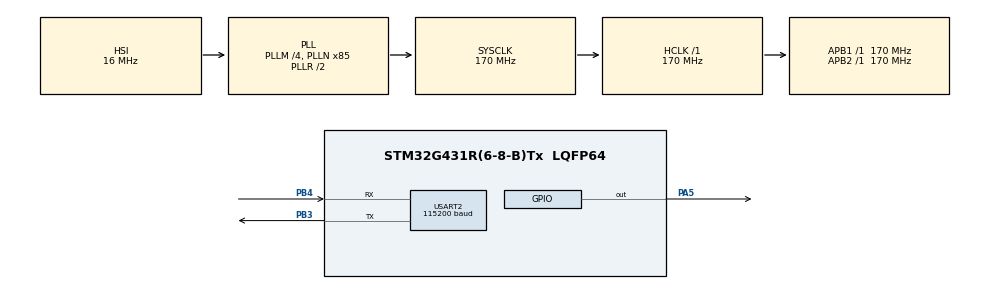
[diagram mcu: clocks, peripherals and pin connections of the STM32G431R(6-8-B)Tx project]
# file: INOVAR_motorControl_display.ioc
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Mcu.Family=STM32G4
Mcu.Name=STM32G431R(6-8-B)Tx
Mcu.Package=LQFP64
NVIC.PriorityGroup=NVIC_PRIORITYGROUP_4
NVIC.TIM1_UP_TIM16_IRQn=true\:15\:0\:false\:false\:true\:false\:true
NVIC.TimeBase=TIM1_UP_TIM16_IRQn
NVIC.TimeBaseIP=TIM1
NVIC.USART2_IRQn=true\:0\:0\:false\:false\:true\:true\:true
PA5.Signal=GPIO_Output
PB3.Mode=Asynchronous
PB3.Signal=USART2_TX
PB4.Mode=Asynchronous
PB4.Signal=USART2_RX
PF0-OSC_IN.Mode=HSE-External-Oscillator
PF0-OSC_IN.Signal=RCC_OSC_IN
PF1-OSC_OUT.Mode=HSE-External-Oscillator
PF1-OSC_OUT.Signal=RCC_OSC_OUT
ProjectManager.HeapSize=0x200
ProjectManager.StackSize=0x400
ProjectManager.TargetToolchain=STM32CubeIDE
RCC.ADC12Freq_Value=170000000
RCC.AHBFreq_Value=170000000
RCC.APB1Freq_Value=170000000
RCC.APB1TimFreq_Value=170000000
RCC.APB2Freq_Value=170000000
RCC.APB2TimFreq_Value=170000000
RCC.CortexFreq_Value=170000000
RCC.EXTERNAL_CLOCK_VALUE=12288000
RCC.HCLKFreq_Value=170000000
RCC.HSE_VALUE=24000000
RCC.HSI48_VALUE=48000000
RCC.HSI_VALUE=16000000
RCC.LSE_VALUE=32768
RCC.PLLM=RCC_PLLM_DIV4
RCC.PLLN=85
RCC.RTCClockSelection=RCC_RTCCLKSOURCE_LSE
RCC.SYSCLKFreq_VALUE=170000000
RCC.SYSCLKSource=RCC_SYSCLKSOURCE_PLLCLK
RCC.USBFreq_Value=170000000
RCC.VCOOutputFreq_Value=340000000
USART2.BaudRate=115200
USART2.VirtualMode-Asynchronous=VM_ASYNC
VP_SYS_VS_DBSignals.Mode=DisableDeadBatterySignals
VP_SYS_VS_tim1.Mode=TIM1
board=NUCLEO-G431RB

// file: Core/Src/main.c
/* USER CODE BEGIN Header */
/**
  ******************************************************************************
  * @file           : main.c
  * @brief          : Main program body
  ******************************************************************************
  * @attention
  *
  * <h2><center>&copy; Copyright (c) 2021 STMicroelectronics.
  * All rights reserved.</center></h2>
  *
  * This software component is licensed by ST under BSD 3-Clause license,
  * the "License"; You may not use this file except in compliance with the
  * License. You may obtain a copy of the License at:
  *                        opensource.org/licenses/BSD-3-Clause
  *
  ******************************************************************************
  */
/* USER CODE END Header */
#include "main.h"

UART_HandleTypeDef huart2;

/* USER CODE BEGIN PV */
uint16_t data,flash_data=0;
/* USER CODE END PV */

void SystemClock_Config(void);
static void MX_GPIO_Init(void);
static void MX_USART2_UART_Init(void);

/* USER CODE BEGIN 0 */

uint32_t rxBuff;
uint16_t buffCounter=0;
uint8_t buffDisplay[99];
 uint8_t Sifrem[4];
 uint8_t Sifrem1[4];
int q,w,e,r,g;
int z,x,c,v;
static uint8_t dataread[4];
uint8_t gelenData_24[4];
uint32_t sayi;
float sayi_;
int i,m,u;
char buff[100];
char buff1[100];

extern bool vitrinac;

extern bool vitrinsifre;

extern bool sifredegis;
//const char rxBuf[20];
//
//uint8_t gelen_mesaj_kutusu[8];
//extern int v,sifrem;
//
//
//uint8_t r;
//uint16_t i,n,m,z;

uint8_t Cmd_End[3] = {0xFF,0xFF,0xFF};

void NEXTION_SendString (char *ID, char *string)
{
	char buf[50];
	int len = sprintf (buf, "%s\%s", ID, string);
	HAL_UART_Transmit(&huart2, (uint8_t *)buf, len, 1000);
	HAL_UART_Transmit(&huart2, Cmd_End, 3, 100);
}

 void SendtoGauge (char *obj, float num, int dp)
 {
	 int32_t number = num*(pow(10,dp));

	 uint8_t *buffer = malloc(30*sizeof(char));

	 int len = sprintf((char *)buffer, "%s.val=%d", obj,number);
	 HAL_UART_Transmit(&huart2, buffer, len, 99);
	 HAL_UART_Transmit(&huart2, Cmd_End, 3, 100);

	 free(buffer);
 }
 void Nextion_Set_Text(char *object_name, char *buffer)
 {
 	char buf[120] = { 0 };
 	char sps = 0xFF;
 	sprintf(buf, "%s.txt=\"%s\"%c%c%c", object_name, buffer, sps, sps, sps);
 	HAL_UART_Transmit(&huart2, (uint8_t*) &buf, strlen(buf), 1000);
 }
/* USER CODE END 0 */

int main(void)
{

  /* MCU Configuration--------------------------------------------------------*/

  /* Reset of all peripherals, Initializes the Flash interface and the Systick. */
  HAL_Init();

  /* Configure the system clock */
  SystemClock_Config();

  /* Initialize all configured peripherals */
  MX_GPIO_Init();
  MX_USART2_UART_Init();
  ee_init();
  /* USER CODE BEGIN 2 */
  __HAL_UART_ENABLE_IT(&huart2, UART_IT_RXNE);

  //static uint8_t datawrite[4] = {1,2,3,4};
  static uint8_t dataread[4];
//  ee_write(0,4,datawrite);
//  ee_read(0,4,dataread);

  ee_read(0,4,dataread);

  /* USER CODE END 2 */

  /* Infinite loop */
  while (1)
  {

    /* USER CODE BEGIN 3 */

	  //Nextion_Set_Text("t1", "SIFRE GIRINIZ");
	     //sayi=(int*)Sifrem;

		// ee_write(0,4,Sifrem),

//	  if(strstr(rxBuf,"SETTING")!=NULL)
//	  {
//		  NEXTION_SendString("page ","5");
//		  memset(rxBuf,'0',sizeof(rxBuf));
//	  }
//	  if(strstr(rxBuf,"@PSWORD_PAGE")!=NULL)
//	  {
//		  NEXTION_SendString("page ","4");
//		  memset(rxBuf,'0',sizeof(rxBuf));
//	  }
//	  if(strstr(rxBuf,"@SIFREM")!=NULL)
//	  {
//		  NEXTION_SendString("page ","4");
//		  if(v==1782)
//		  {
//			  NEXTION_SendString("page ","1");
//		  }
//	  }
//	  if(strstr(rxBuf,"OPENTHEDOOR")!=NULL)
//	  {
//		  NEXTION_SendString("page ","4");
//		  if(v==1782)
//		  {
//			  NEXTION_SendString("page ","2");
//		  }
//	  }
//	  if(strstr(rxBuf,"START")!=NULL)
//	  {
//		  NEXTION_SendString("page ","3");
//		  memset(rxBuf,'0',sizeof(rxBuf));
//
//	  }
//	  if(strstr(rxBuf,"STOP")!=NULL)
//	  {
//		  NEXTION_SendString("page ","2");
//		  memset(rxBuf,'0',sizeof(rxBuf));
//
//	  }

  }
  /* USER CODE END 3 */
}

void SystemClock_Config(void)
{
  RCC_OscInitTypeDef RCC_OscInitStruct = {0};
  RCC_ClkInitTypeDef RCC_ClkInitStruct = {0};
  RCC_PeriphCLKInitTypeDef PeriphClkInit = {0};

  /** Configure the main internal regulator output voltage
  */
  HAL_PWREx_ControlVoltageScaling(PWR_REGULATOR_VOLTAGE_SCALE1_BOOST);
  /** Initializes the RCC Oscillators according to the specified parameters
  * in the RCC_OscInitTypeDef structure.
  */
  RCC_OscInitStruct.OscillatorType = RCC_OSCILLATORTYPE_HSI;
  RCC_OscInitStruct.HSIState = RCC_HSI_ON;
  RCC_OscInitStruct.HSICalibrationValue = RCC_HSICALIBRATION_DEFAULT;
  RCC_OscInitStruct.PLL.PLLState = RCC_PLL_ON;
  RCC_OscInitStruct.PLL.PLLSource = RCC_PLLSOURCE_HSI;
  RCC_OscInitStruct.PLL.PLLM = RCC_PLLM_DIV4;
  RCC_OscInitStruct.PLL.PLLN = 85;
  RCC_OscInitStruct.PLL.PLLP = RCC_PLLP_DIV2;
  RCC_OscInitStruct.PLL.PLLQ = RCC_PLLQ_DIV2;
  RCC_OscInitStruct.PLL.PLLR = RCC_PLLR_DIV2;
  if (HAL_RCC_OscConfig(&RCC_OscInitStruct) != HAL_OK)
  {
    Error_Handler();
  }
  /** Initializes the CPU, AHB and APB buses clocks
  */
  RCC_ClkInitStruct.ClockType = RCC_CLOCKTYPE_HCLK|RCC_CLOCKTYPE_SYSCLK
                              |RCC_CLOCKTYPE_PCLK1|RCC_CLOCKTYPE_PCLK2;
  RCC_ClkInitStruct.SYSCLKSource = RCC_SYSCLKSOURCE_PLLCLK;
  RCC_ClkInitStruct.AHBCLKDivider = RCC_SYSCLK_DIV1;
  RCC_ClkInitStruct.APB1CLKDivider = RCC_HCLK_DIV1;
  RCC_ClkInitStruct.APB2CLKDivider = RCC_HCLK_DIV1;

  if (HAL_RCC_ClockConfig(&RCC_ClkInitStruct, FLASH_LATENCY_4) != HAL_OK)
  {
    Error_Handler();
  }
  /** Initializes the peripherals clocks
  */
  PeriphClkInit.PeriphClockSelection = RCC_PERIPHCLK_USART2;
  PeriphClkInit.Usart2ClockSelection = RCC_USART2CLKSOURCE_PCLK1;
  if (HAL_RCCEx_PeriphCLKConfig(&PeriphClkInit) != HAL_OK)
  {
    Error_Handler();
  }
}

static void MX_USART2_UART_Init(void)
{

  huart2.Instance = USART2;
  huart2.Init.BaudRate = 115200;
  huart2.Init.WordLength = UART_WORDLENGTH_8B;
  huart2.Init.StopBits = UART_STOPBITS_1;
  huart2.Init.Parity = UART_PARITY_NONE;
  huart2.Init.Mode = UART_MODE_TX_RX;
  huart2.Init.HwFlowCtl = UART_HWCONTROL_NONE;
  huart2.Init.OverSampling = UART_OVERSAMPLING_16;
  huart2.Init.OneBitSampling = UART_ONE_BIT_SAMPLE_DISABLE;
  huart2.Init.ClockPrescaler = UART_PRESCALER_DIV1;
  huart2.AdvancedInit.AdvFeatureInit = UART_ADVFEATURE_NO_INIT;
  if (HAL_UART_Init(&huart2) != HAL_OK)
  {
    Error_Handler();
  }
  if (HAL_UARTEx_SetTxFifoThreshold(&huart2, UART_TXFIFO_THRESHOLD_1_8) != HAL_OK)
  {
    Error_Handler();
  }
  if (HAL_UARTEx_SetRxFifoThreshold(&huart2, UART_RXFIFO_THRESHOLD_1_8) != HAL_OK)
  {
    Error_Handler();
  }
  if (HAL_UARTEx_DisableFifoMode(&huart2) != HAL_OK)
  {
    Error_Handler();
  }

}

static void MX_GPIO_Init(void)
{
  GPIO_InitTypeDef GPIO_InitStruct = {0};

  /* GPIO Ports Clock Enable */
  __HAL_RCC_GPIOF_CLK_ENABLE();
  __HAL_RCC_GPIOA_CLK_ENABLE();
  __HAL_RCC_GPIOB_CLK_ENABLE();

  /*Configure GPIO pin Output Level */
  HAL_GPIO_WritePin(GPIOA, GPIO_PIN_5, GPIO_PIN_RESET);

  /*Configure GPIO pin : PA5 */
  GPIO_InitStruct.Pin = GPIO_PIN_5;
  GPIO_InitStruct.Mode = GPIO_MODE_OUTPUT_PP;
  GPIO_InitStruct.Pull = GPIO_NOPULL;
  GPIO_InitStruct.Speed = GPIO_SPEED_FREQ_LOW;
  HAL_GPIO_Init(GPIOA, &GPIO_InitStruct);

}

void HAL_TIM_PeriodElapsedCallback(TIM_HandleTypeDef *htim)
{
  if (htim->Instance == TIM1) {
    HAL_IncTick();
  }
}

void Error_Handler(void)
{
  __disable_irq();
  while (1)
  {
  }
}

/************************ (C) COPYRIGHT STMicroelectronics *****END OF FILE****/
